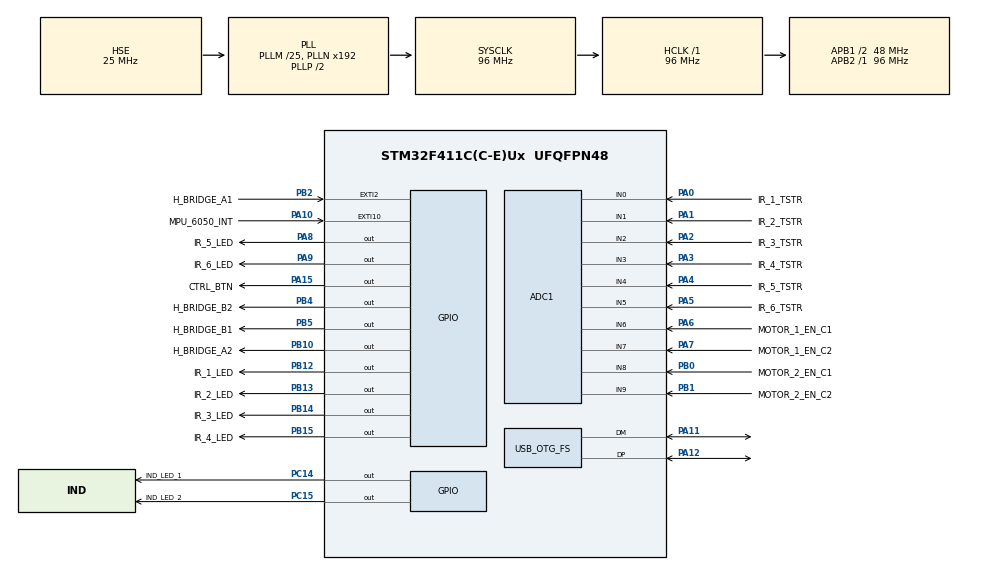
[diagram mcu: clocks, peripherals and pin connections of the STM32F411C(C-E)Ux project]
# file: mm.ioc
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ADC1.Channel-0\#ChannelRegularConversion=ADC_CHANNEL_0
ADC1.NbrOfConversionFlag=1
ADC1.Rank-0\#ChannelRegularConversion=1
ADC1.SamplingTime-0\#ChannelRegularConversion=ADC_SAMPLETIME_3CYCLES
ADC1.master=1
Mcu.Family=STM32F4
Mcu.Name=STM32F411C(C-E)Ux
Mcu.Package=UFQFPN48
NVIC.OTG_FS_IRQn=true\:0\:0\:false\:false\:true\:false\:true\:true
NVIC.PriorityGroup=NVIC_PRIORITYGROUP_4
PA0-WKUP.GPIO_Label=IR_1_TSTR
PA0-WKUP.Signal=ADCx_IN0
PA1.GPIO_Label=IR_2_TSTR
PA1.Signal=ADCx_IN1
PA10.GPIO_Label=MPU_6050_INT
PA10.Signal=GPXTI10
PA11.Mode=Device_Only
PA11.Signal=USB_OTG_FS_DM
PA12.Mode=Device_Only
PA12.Signal=USB_OTG_FS_DP
PA13.Mode=Trace_Asynchronous_SW
PA13.Signal=SYS_JTMS-SWDIO
PA14.Mode=Trace_Asynchronous_SW
PA14.Signal=SYS_JTCK-SWCLK
PA15.GPIO_Label=CTRL_BTN
PA15.Signal=GPIO_Output
PA2.GPIO_Label=IR_3_TSTR
PA2.Signal=ADCx_IN2
PA3.GPIO_Label=IR_4_TSTR
PA3.Signal=ADCx_IN3
PA4.GPIO_Label=IR_5_TSTR
PA4.Signal=ADCx_IN4
PA5.GPIO_Label=IR_6_TSTR
PA5.Signal=ADCx_IN5
PA6.GPIO_Label=MOTOR_1_EN_C1
PA6.Signal=ADCx_IN6
PA7.GPIO_Label=MOTOR_1_EN_C2
PA7.Signal=ADCx_IN7
PA8.GPIO_Label=IR_5_LED
PA8.Signal=GPIO_Output
PA9.GPIO_Label=IR_6_LED
PA9.Signal=GPIO_Output
PB0.GPIO_Label=MOTOR_2_EN_C1
PB0.Signal=ADCx_IN8
PB1.GPIO_Label=MOTOR_2_EN_C2
PB1.Signal=ADCx_IN9
PB10.GPIO_Label=H_BRIDGE_A2
PB10.Signal=GPIO_Output
PB12.GPIO_Label=IR_1_LED
PB12.Signal=GPIO_Output
PB13.GPIO_Label=IR_2_LED
PB13.Signal=GPIO_Output
PB14.GPIO_Label=IR_3_LED
PB14.Signal=GPIO_Output
PB15.GPIO_Label=IR_4_LED
PB15.Signal=GPIO_Output
PB2.GPIO_Label=H_BRIDGE_A1
PB2.Signal=GPXTI2
PB3.Mode=Trace_Asynchronous_SW
PB3.Signal=SYS_JTDO-SWO
PB4.GPIO_Label=H_BRIDGE_B2
PB4.Signal=GPIO_Output
PB5.GPIO_Label=H_BRIDGE_B1
PB5.Signal=GPIO_Output
PB6.GPIO_Label=DRV_8833_MOTOR_2_IN_1
PB6.Signal=S_TIM4_CH1
PB7.GPIO_Label=DRV_8833_MOTOR_2_IN_2
PB7.Signal=S_TIM4_CH2
PB8.GPIO_Label=MPU_6050_TOF_SCL
PB8.Signal=I2C1_SCL
PB9.GPIO_Label=MPU_6050_TOF_SDA
PB9.Signal=I2C1_SDA
PC14-OSC32_IN.GPIO_Label=IND_LED_1
PC14-OSC32_IN.Signal=GPIO_Output
PC15-OSC32_OUT.GPIO_Label=IND_LED_2
PC15-OSC32_OUT.Signal=GPIO_Output
PH0\ -\ OSC_IN.Mode=HSE-External-Oscillator
PH0\ -\ OSC_IN.Signal=RCC_OSC_IN
PH1\ -\ OSC_OUT.Mode=HSE-External-Oscillator
PH1\ -\ OSC_OUT.Signal=RCC_OSC_OUT
ProjectManager.HeapSize=0x200
ProjectManager.StackSize=0x400
ProjectManager.TargetToolchain=STM32CubeIDE
RCC.48MHZClocksFreq_Value=48000000
RCC.AHBFreq_Value=96000000
RCC.APB1CLKDivider=RCC_HCLK_DIV2
RCC.APB1Freq_Value=48000000
RCC.APB1TimFreq_Value=96000000
RCC.APB2Freq_Value=96000000
RCC.APB2TimFreq_Value=96000000
RCC.CortexFreq_Value=96000000
RCC.HCLKFreq_Value=96000000
RCC.HSE_VALUE=25000000
RCC.HSI_VALUE=16000000
RCC.LSE_VALUE=32768
RCC.PLLM=25
RCC.SYSCLKFreq_VALUE=96000000
RCC.SYSCLKSource=RCC_SYSCLKSOURCE_PLLCLK
RCC.VCOOutputFreq_Value=192000000
SH.ADCx_IN0.0=ADC1_IN0,IN0
SH.ADCx_IN1.0=ADC1_IN1,IN1
SH.ADCx_IN2.0=ADC1_IN2,IN2
SH.ADCx_IN3.0=ADC1_IN3,IN3
SH.ADCx_IN4.0=ADC1_IN4,IN4
SH.ADCx_IN5.0=ADC1_IN5,IN5
SH.ADCx_IN6.0=ADC1_IN6,IN6
SH.ADCx_IN7.0=ADC1_IN7,IN7
SH.ADCx_IN8.0=ADC1_IN8,IN8
SH.ADCx_IN9.0=ADC1_IN9,IN9
SH.S_TIM4_CH1.0=TIM4_CH1
SH.S_TIM4_CH2.0=TIM4_CH2
USB_DEVICE.CLASS_NAME_FS=CDC
USB_DEVICE.VirtualMode=Cdc
USB_DEVICE.VirtualModeFS=Cdc_FS
USB_OTG_FS.VirtualMode=Device_Only
VP_USB_DEVICE_VS_USB_DEVICE_CDC_FS.Mode=CDC_FS
board=custom

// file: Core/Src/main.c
/* USER CODE BEGIN Header */
/**
  ******************************************************************************
  * @file           : main.c
  * @brief          : Main program body
  ******************************************************************************
  * @attention
  *
  * Copyright (c) 2024 STMicroelectronics.
  * All rights reserved.
  *
  * This software is licensed under terms that can be found in the LICENSE file
  * in the root directory of this software component.
  * If no LICENSE file comes with this software, it is provided AS-IS.
  *
  ******************************************************************************
  */
/* USER CODE END Header */
#include "main.h"
#include "usb_device.h"
/* USER CODE BEGIN Includes */
#include <stdint.h>
#include "config.h"
#include "global_vars.h"
#include "helper.h"
#include "ir_secondary.h"
#include "pid_interupt.h"
#include "map_update_interrupt.h"
#include "rotational_motion.h"
#include "linear_motion.h"
#include "ir_interupt.h"

/* USER CODE END Includes */

ADC_HandleTypeDef hadc1;

void SystemClock_Config(void);
static void MX_GPIO_Init(void);
static void MX_ADC1_Init(void);

int main(void)
{

  /* MCU Configuration--------------------------------------------------------*/

  /* Reset of all peripherals, Initializes the Flash interface and the Systick. */
  HAL_Init();

  /* Configure the system clock */
  SystemClock_Config();

  /* Initialize all configured peripherals */
  MX_GPIO_Init();
  MX_ADC1_Init();
  MX_USB_DEVICE_Init();

  /* Infinite loop */
  while (1)
  {

  }
}

void SystemClock_Config(void)
{
  RCC_OscInitTypeDef RCC_OscInitStruct = {0};
  RCC_ClkInitTypeDef RCC_ClkInitStruct = {0};

  /** Configure the main internal regulator output voltage
  */
  __HAL_RCC_PWR_CLK_ENABLE();
  __HAL_PWR_VOLTAGESCALING_CONFIG(PWR_REGULATOR_VOLTAGE_SCALE1);

  /** Initializes the RCC Oscillators according to the specified parameters
  * in the RCC_OscInitTypeDef structure.
  */
  RCC_OscInitStruct.OscillatorType = RCC_OSCILLATORTYPE_HSE;
  RCC_OscInitStruct.HSEState = RCC_HSE_ON;
  RCC_OscInitStruct.PLL.PLLState = RCC_PLL_ON;
  RCC_OscInitStruct.PLL.PLLSource = RCC_PLLSOURCE_HSE;
  RCC_OscInitStruct.PLL.PLLM = 25;
  RCC_OscInitStruct.PLL.PLLN = 192;
  RCC_OscInitStruct.PLL.PLLP = RCC_PLLP_DIV2;
  RCC_OscInitStruct.PLL.PLLQ = 4;
  if (HAL_RCC_OscConfig(&RCC_OscInitStruct) != HAL_OK)
  {
    Error_Handler();
  }

  /** Initializes the CPU, AHB and APB buses clocks
  */
  RCC_ClkInitStruct.ClockType = RCC_CLOCKTYPE_HCLK|RCC_CLOCKTYPE_SYSCLK
                              |RCC_CLOCKTYPE_PCLK1|RCC_CLOCKTYPE_PCLK2;
  RCC_ClkInitStruct.SYSCLKSource = RCC_SYSCLKSOURCE_PLLCLK;
  RCC_ClkInitStruct.AHBCLKDivider = RCC_SYSCLK_DIV1;
  RCC_ClkInitStruct.APB1CLKDivider = RCC_HCLK_DIV2;
  RCC_ClkInitStruct.APB2CLKDivider = RCC_HCLK_DIV1;

  if (HAL_RCC_ClockConfig(&RCC_ClkInitStruct, FLASH_LATENCY_3) != HAL_OK)
  {
    Error_Handler();
  }
}

static void MX_ADC1_Init(void)
{

  ADC_ChannelConfTypeDef sConfig = {0};

  /** Configure the global features of the ADC (Clock, Resolution, Data Alignment and number of conversion)
  */
  hadc1.Instance = ADC1;
  hadc1.Init.ClockPrescaler = ADC_CLOCK_SYNC_PCLK_DIV4;
  hadc1.Init.Resolution = ADC_RESOLUTION_12B;
  hadc1.Init.ScanConvMode = DISABLE;
  hadc1.Init.ContinuousConvMode = DISABLE;
  hadc1.Init.DiscontinuousConvMode = DISABLE;
  hadc1.Init.ExternalTrigConvEdge = ADC_EXTERNALTRIGCONVEDGE_NONE;
  hadc1.Init.ExternalTrigConv = ADC_SOFTWARE_START;
  hadc1.Init.DataAlign = ADC_DATAALIGN_RIGHT;
  hadc1.Init.NbrOfConversion = 1;
  hadc1.Init.DMAContinuousRequests = DISABLE;
  hadc1.Init.EOCSelection = ADC_EOC_SINGLE_CONV;
  if (HAL_ADC_Init(&hadc1) != HAL_OK)
  {
    Error_Handler();
  }

  /** Configure for the selected ADC regular channel its corresponding rank in the sequencer and its sample time.
  */
  sConfig.Channel = ADC_CHANNEL_0;
  sConfig.Rank = 1;
  sConfig.SamplingTime = ADC_SAMPLETIME_3CYCLES;
  if (HAL_ADC_ConfigChannel(&hadc1, &sConfig) != HAL_OK)
  {
    Error_Handler();
  }

}

static void MX_GPIO_Init(void)
{
  GPIO_InitTypeDef GPIO_InitStruct = {0};

  /* GPIO Ports Clock Enable */
  __HAL_RCC_GPIOC_CLK_ENABLE();
  __HAL_RCC_GPIOH_CLK_ENABLE();
  __HAL_RCC_GPIOA_CLK_ENABLE();
  __HAL_RCC_GPIOB_CLK_ENABLE();

  /*Configure GPIO pin Output Level */
  HAL_GPIO_WritePin(GPIOC, IND_LED_1_Pin|IND_LED_2_Pin, GPIO_PIN_RESET);

  /*Configure GPIO pin Output Level */
  HAL_GPIO_WritePin(GPIOB, H_BRIDGE_A2_Pin|IR_1_LED_Pin|IR_2_LED_Pin|IR_3_LED_Pin
                          |IR_4_LED_Pin|H_BRIDGE_B2_Pin|H_BRIDGE_B1_Pin, GPIO_PIN_RESET);

  /*Configure GPIO pin Output Level */
  HAL_GPIO_WritePin(GPIOA, IR_5_LED_Pin|IR_6_LED_Pin|CTRL_BTN_Pin, GPIO_PIN_RESET);

  /*Configure GPIO pins : IND_LED_1_Pin IND_LED_2_Pin */
  GPIO_InitStruct.Pin = IND_LED_1_Pin|IND_LED_2_Pin;
  GPIO_InitStruct.Mode = GPIO_MODE_OUTPUT_PP;
  GPIO_InitStruct.Pull = GPIO_NOPULL;
  GPIO_InitStruct.Speed = GPIO_SPEED_FREQ_LOW;
  HAL_GPIO_Init(GPIOC, &GPIO_InitStruct);

  /*Configure GPIO pin : H_BRIDGE_A1_Pin */
  GPIO_InitStruct.Pin = H_BRIDGE_A1_Pin;
  GPIO_InitStruct.Mode = GPIO_MODE_IT_RISING;
  GPIO_InitStruct.Pull = GPIO_NOPULL;
  HAL_GPIO_Init(H_BRIDGE_A1_GPIO_Port, &GPIO_InitStruct);

  /*Configure GPIO pins : H_BRIDGE_A2_Pin IR_1_LED_Pin IR_2_LED_Pin IR_3_LED_Pin
                           IR_4_LED_Pin H_BRIDGE_B2_Pin H_BRIDGE_B1_Pin */
  GPIO_InitStruct.Pin = H_BRIDGE_A2_Pin|IR_1_LED_Pin|IR_2_LED_Pin|IR_3_LED_Pin
                          |IR_4_LED_Pin|H_BRIDGE_B2_Pin|H_BRIDGE_B1_Pin;
  GPIO_InitStruct.Mode = GPIO_MODE_OUTPUT_PP;
  GPIO_InitStruct.Pull = GPIO_NOPULL;
  GPIO_InitStruct.Speed = GPIO_SPEED_FREQ_LOW;
  HAL_GPIO_Init(GPIOB, &GPIO_InitStruct);

  /*Configure GPIO pins : IR_5_LED_Pin IR_6_LED_Pin CTRL_BTN_Pin */
  GPIO_InitStruct.Pin = IR_5_LED_Pin|IR_6_LED_Pin|CTRL_BTN_Pin;
  GPIO_InitStruct.Mode = GPIO_MODE_OUTPUT_PP;
  GPIO_InitStruct.Pull = GPIO_NOPULL;
  GPIO_InitStruct.Speed = GPIO_SPEED_FREQ_LOW;
  HAL_GPIO_Init(GPIOA, &GPIO_InitStruct);

  /*Configure GPIO pin : MPU_6050_INT_Pin */
  GPIO_InitStruct.Pin = MPU_6050_INT_Pin;
  GPIO_InitStruct.Mode = GPIO_MODE_IT_RISING;
  GPIO_InitStruct.Pull = GPIO_NOPULL;
  HAL_GPIO_Init(MPU_6050_INT_GPIO_Port, &GPIO_InitStruct);

  /*Configure GPIO pins : DRV_8833_MOTOR_2_IN_1_Pin DRV_8833_MOTOR_2_IN_2_Pin */
  GPIO_InitStruct.Pin = DRV_8833_MOTOR_2_IN_1_Pin|DRV_8833_MOTOR_2_IN_2_Pin;
  GPIO_InitStruct.Mode = GPIO_MODE_AF_PP;
  GPIO_InitStruct.Pull = GPIO_NOPULL;
  GPIO_InitStruct.Speed = GPIO_SPEED_FREQ_LOW;
  GPIO_InitStruct.Alternate = GPIO_AF2_TIM4;
  HAL_GPIO_Init(GPIOB, &GPIO_InitStruct);

  /*Configure GPIO pins : MPU_6050_TOF_SCL_Pin MPU_6050_TOF_SDA_Pin */
  GPIO_InitStruct.Pin = MPU_6050_TOF_SCL_Pin|MPU_6050_TOF_SDA_Pin;
  GPIO_InitStruct.Mode = GPIO_MODE_AF_OD;
  GPIO_InitStruct.Pull = GPIO_NOPULL;
  GPIO_InitStruct.Speed = GPIO_SPEED_FREQ_VERY_HIGH;
  GPIO_InitStruct.Alternate = GPIO_AF4_I2C1;
  HAL_GPIO_Init(GPIOB, &GPIO_InitStruct);

}

void Error_Handler(void)
{
  __disable_irq();
  while (1)
  {
  }
}
